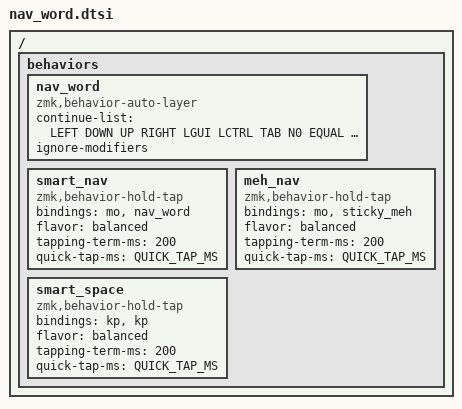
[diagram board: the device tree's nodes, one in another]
#include <dt-bindings/zmk/behaviors.h>
#include <dt-bindings/zmk/keys.h>

/ {
    behaviors {
        nav_word: nav_word {
            compatible = "zmk,behavior-auto-layer";
            #binding-cells = <1>;
            continue-list = <LEFT DOWN UP RIGHT LGUI LCTRL TAB N0 EQUAL MINUS DEL BSPC>;
            ignore-modifiers;
        };
    };
};

// Tap: nav-word  | Hold: nav-layer.
#define SMART_NAV &smart_nav NAV NAV
ZMK_HOLD_TAP(smart_nav, bindings = <&mo>, <&nav_word>; flavor = "balanced";
             tapping-term-ms = <200>; quick-tap-ms = <QUICK_TAP_MS>;)

// Tap: Sticky Meh (GUI+Shift+Alt)  | Hold: nav-layer.
#define MEH_NAV &meh_nav NAV 0
ZMK_HOLD_TAP(meh_nav, bindings = <&mo>, <&sticky_meh>; flavor = "balanced";
             tapping-term-ms = <200>; quick-tap-ms = <QUICK_TAP_MS>;)

// Tap: space  | Hold: LCTL.
#define SMART_SPACE &smart_space LCTL SPACE
ZMK_HOLD_TAP(smart_space, bindings = <&kp>, <&kp>; flavor = "balanced";
             tapping-term-ms = <200>; quick-tap-ms = <QUICK_TAP_MS>;)
